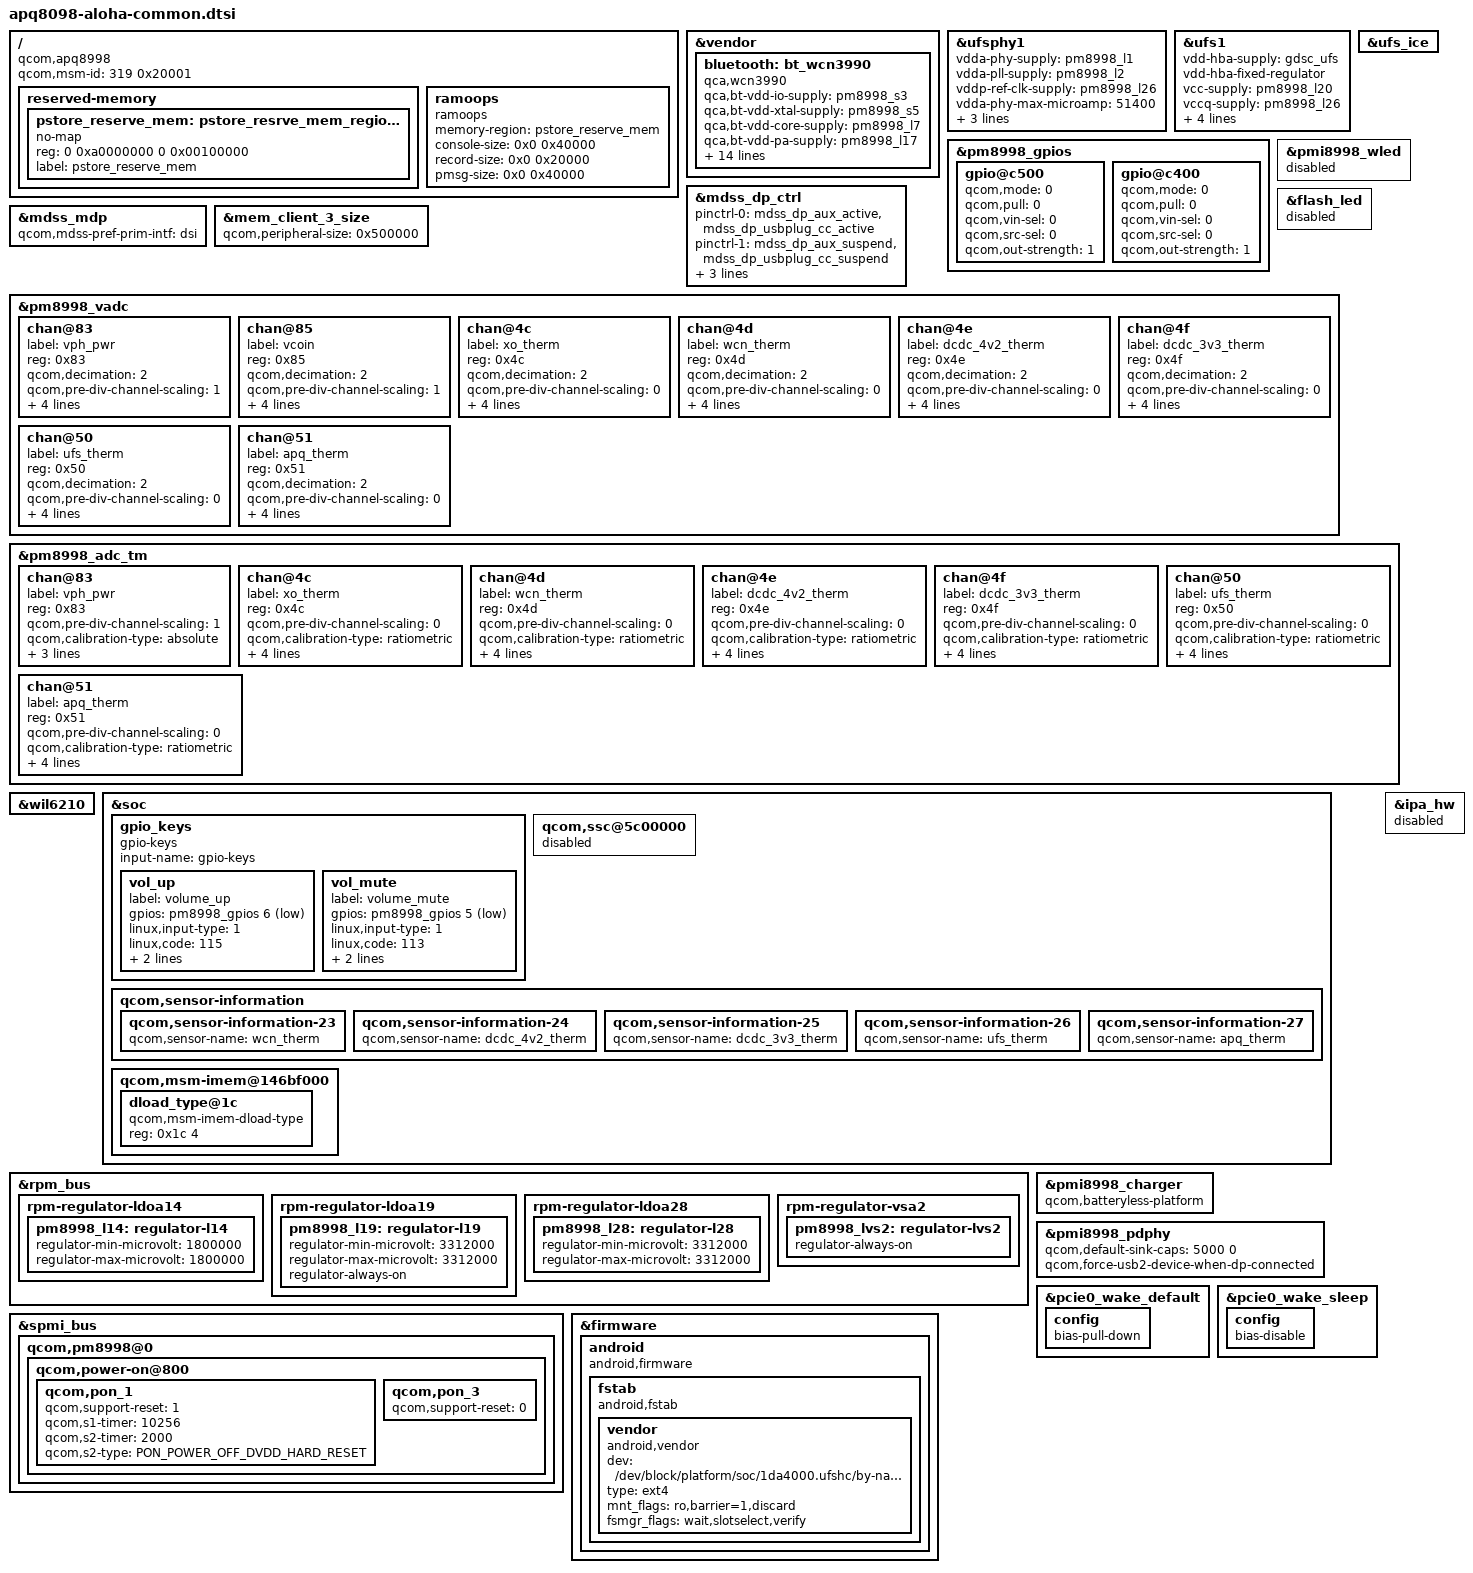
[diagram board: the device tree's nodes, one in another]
/* Copyright (c) 2014-2017, The Linux Foundation. All rights reserved.
 *
 * This program is free software; you can redistribute it and/or modify
 * it under the terms of the GNU General Public License version 2 and
 * only version 2 as published by the Free Software Foundation.
 *
 * This program is distributed in the hope that it will be useful,
 * but WITHOUT ANY WARRANTY; without even the implied warranty of
 * MERCHANTABILITY or FITNESS FOR A PARTICULAR PURPOSE.  See the
 * GNU General Public License for more details.
 */

/dts-v1/;

#include <dt-bindings/interrupt-controller/irq.h>
#include "../qcom/msm8998-v2.1.dtsi"
#include "../qcom/msm8998-pinctrl.dtsi"

/ {
	compatible = "qcom,apq8998", "qcom,apq8098-aloha";
	qcom,msm-id = <319 0x20001>;
};

&vendor {
	bluetooth: bt_wcn3990 {
		compatible = "qca,wcn3990";
		qca,bt-vdd-io-supply = <&pm8998_s3>;
		qca,bt-vdd-xtal-supply = <&pm8998_s5>;
		qca,bt-vdd-core-supply = <&pm8998_l7>;
		qca,bt-vdd-pa-supply = <&pm8998_l17>;
		qca,bt-vdd-ldo-supply = <&pm8998_l25>;
		qca,bt-chip-pwd-supply = <&pmi8998_bob_pin1>;
		clocks = <&clock_gcc clk_rf_clk2_pin>;
		clock-names = "rf_clk2";

		qca,bt-vdd-io-voltage-level = <1352000 1352000>;
		qca,bt-vdd-xtal-voltage-level = <2040000 2040000>;
		qca,bt-vdd-core-voltage-level = <1800000 1800000>;
		qca,bt-vdd-pa-voltage-level = <1304000 1304000>;
		qca,bt-vdd-ldo-voltage-level = <3312000 3312000>;
		qca,bt-chip-pwd-voltage-level = <3600000 3600000>;

		qca,bt-vdd-io-current-level = <1>; /* LPM/PFM */
		qca,bt-vdd-xtal-current-level = <1>; /* LPM/PFM */
		qca,bt-vdd-core-current-level = <1>; /* LPM/PFM */
		qca,bt-vdd-pa-current-level = <1>; /* LPM/PFM */
		qca,bt-vdd-ldo-current-level = <1>; /* LPM/PFM */
	};
};

/ {
	reserved-memory {
		pstore_reserve_mem: pstore_resrve_mem_region@a0000000 {
			no-map;
			reg = <0 0xa0000000 0 0x00100000>;
			label = "pstore_reserve_mem";
		};
	};

	ramoops {
		compatible = "ramoops";
		memory-region = <&pstore_reserve_mem>;
		console-size = <0x0 0x40000>;
		record-size = <0x0 0x20000>;
		pmsg-size = <0x0 0x40000>;
	};
};

&ufsphy1 {
	vdda-phy-supply = <&pm8998_l1>;
	vdda-pll-supply = <&pm8998_l2>;
	vddp-ref-clk-supply = <&pm8998_l26>;
	vdda-phy-max-microamp = <51400>;
	vdda-pll-max-microamp = <14600>;
	vddp-ref-clk-max-microamp = <100>;
	vddp-ref-clk-always-on;
	status = "ok";
};

&ufs1 {
	vdd-hba-supply = <&gdsc_ufs>;
	vdd-hba-fixed-regulator;
	vcc-supply = <&pm8998_l20>;
	vccq-supply = <&pm8998_l26>;
	vccq2-supply = <&pm8998_s4>;
	vcc-max-microamp = <750000>;
	vccq-max-microamp = <560000>;
	vccq2-max-microamp = <750000>;
	status = "ok";
};

&ufs_ice {
	status = "ok";
};

&pm8998_gpios {
	/* GPIO 6 for Vol+ Key */
	gpio@c500 {
		status = "okay";
		qcom,mode = <0>;
		qcom,pull = <0>;
		qcom,vin-sel = <0>;
		qcom,src-sel = <0>;
		qcom,out-strength = <1>;
	};

	/* GPIO 5 for Mute Key */
	gpio@c400 {
		status = "okay";
		qcom,mode = <0>;
		qcom,pull = <0>;
		qcom,vin-sel = <0>;
		qcom,src-sel = <0>;
		qcom,out-strength = <1>;
	};
};

&mdss_dp_ctrl {
	pinctrl-names = "mdss_dp_active", "mdss_dp_sleep";
	pinctrl-0 = <&mdss_dp_aux_active &mdss_dp_usbplug_cc_active>;
	pinctrl-1 = <&mdss_dp_aux_suspend &mdss_dp_usbplug_cc_suspend>;
	qcom,aux-en-gpio = <&tlmm 77 0>;
	qcom,aux-sel-gpio = <&tlmm 78 0>;
	qcom,usbplug-cc-gpio = <&tlmm 38 0>;
};

&mdss_mdp {
	qcom,mdss-pref-prim-intf = "dsi";
};

&pmi8998_wled {
	status = "disabled";
};

&flash_led {
	status = "disabled";
};

&mem_client_3_size {
	qcom,peripheral-size = <0x500000>;
};


&pm8998_vadc {
	chan@83 {
		label = "vph_pwr";
		reg = <0x83>;
		qcom,decimation = <2>;
		qcom,pre-div-channel-scaling = <1>;
		qcom,calibration-type = "absolute";
		qcom,scale-function = <0>;
		qcom,hw-settle-time = <0>;
		qcom,fast-avg-setup = <0>;
	};

	chan@85 {
		label = "vcoin";
		reg = <0x85>;
		qcom,decimation = <2>;
		qcom,pre-div-channel-scaling = <1>;
		qcom,calibration-type = "absolute";
		qcom,scale-function = <0>;
		qcom,hw-settle-time = <0>;
		qcom,fast-avg-setup = <0>;
	};

	chan@4c {
		label = "xo_therm";
		reg = <0x4c>;
		qcom,decimation = <2>;
		qcom,pre-div-channel-scaling = <0>;
		qcom,calibration-type = "ratiometric";
		qcom,scale-function = <4>;
		qcom,hw-settle-time = <2>;
		qcom,fast-avg-setup = <0>;
	};

	chan@4d {
		label = "wcn_therm";
		reg = <0x4d>;
		qcom,decimation = <2>;
		qcom,pre-div-channel-scaling = <0>;
		qcom,calibration-type = "ratiometric";
		qcom,scale-function = <2>;
		qcom,hw-settle-time = <2>;
		qcom,fast-avg-setup = <0>;
	};

	chan@4e {
		label = "dcdc_4v2_therm";
		reg = <0x4e>;
		qcom,decimation = <2>;
		qcom,pre-div-channel-scaling = <0>;
		qcom,calibration-type = "ratiometric";
		qcom,scale-function = <2>;
		qcom,hw-settle-time = <2>;
		qcom,fast-avg-setup = <0>;
	};

	chan@4f {
		label = "dcdc_3v3_therm";
		reg = <0x4f>;
		qcom,decimation = <2>;
		qcom,pre-div-channel-scaling = <0>;
		qcom,calibration-type = "ratiometric";
		qcom,scale-function = <2>;
		qcom,hw-settle-time = <2>;
		qcom,fast-avg-setup = <0>;
	};

	chan@50 {
		label = "ufs_therm";
		reg = <0x50>;
		qcom,decimation = <2>;
		qcom,pre-div-channel-scaling = <0>;
		qcom,calibration-type = "ratiometric";
		qcom,scale-function = <2>;
		qcom,hw-settle-time = <2>;
		qcom,fast-avg-setup = <0>;
	};

	chan@51 {
		label = "apq_therm";
		reg = <0x51>;
		qcom,decimation = <2>;
		qcom,pre-div-channel-scaling = <0>;
		qcom,calibration-type = "ratiometric";
		qcom,scale-function = <2>;
		qcom,hw-settle-time = <2>;
		qcom,fast-avg-setup = <0>;
	};
};

&pm8998_adc_tm {
	chan@83 {
		label = "vph_pwr";
		reg = <0x83>;
		qcom,pre-div-channel-scaling = <1>;
		qcom,calibration-type = "absolute";
		qcom,scale-function = <0>;
		qcom,hw-settle-time = <0>;
		qcom,btm-channel-number = <0x60>;
	};

	chan@4c {
		label = "xo_therm";
		reg = <0x4c>;
		qcom,pre-div-channel-scaling = <0>;
		qcom,calibration-type = "ratiometric";
		qcom,scale-function = <4>;
		qcom,hw-settle-time = <2>;
		qcom,btm-channel-number = <0x68>;
		qcom,thermal-node;
	};

	chan@4d {
		label = "wcn_therm";
		reg = <0x4d>;
		qcom,pre-div-channel-scaling = <0>;
		qcom,calibration-type = "ratiometric";
		qcom,scale-function = <2>;
		qcom,hw-settle-time = <2>;
		qcom,btm-channel-number = <0x70>;
		qcom,thermal-node;
	};

	chan@4e {
		label = "dcdc_4v2_therm";
		reg = <0x4e>;
		qcom,pre-div-channel-scaling = <0>;
		qcom,calibration-type = "ratiometric";
		qcom,scale-function = <4>;
		qcom,hw-settle-time = <2>;
		qcom,btm-channel-number = <0x78>;
		qcom,thermal-node;
	};

	chan@4f {
		label = "dcdc_3v3_therm";
		reg = <0x4f>;
		qcom,pre-div-channel-scaling = <0>;
		qcom,calibration-type = "ratiometric";
		qcom,scale-function = <4>;
		qcom,hw-settle-time = <2>;
		qcom,btm-channel-number = <0x80>;
		qcom,thermal-node;
	};

	chan@50 {
		label = "ufs_therm";
		reg = <0x50>;
		qcom,pre-div-channel-scaling = <0>;
		qcom,calibration-type = "ratiometric";
		qcom,scale-function = <4>;
		qcom,hw-settle-time = <2>;
		qcom,btm-channel-number = <0x88>;
		qcom,thermal-node;
	};

	chan@51 {
		label = "apq_therm";
		reg = <0x51>;
		qcom,pre-div-channel-scaling = <0>;
		qcom,calibration-type = "ratiometric";
		qcom,scale-function = <2>;
		qcom,hw-settle-time = <2>;
		qcom,btm-channel-number = <0x90>;
		qcom,thermal-node;
	};
};

&wil6210 {
	status = "ok";
};

&soc {
	gpio_keys {
		compatible = "gpio-keys";
		input-name = "gpio-keys";
		status = "okay";

		vol_up {
			label = "volume_up";
			gpios = <&pm8998_gpios 6 0x1>;
			linux,input-type = <1>;
			linux,code = <115>;
			gpio-key,wakeup;
			debounce-interval = <15>;
		};

		vol_mute {
			label = "volume_mute";
			gpios = <&pm8998_gpios 5 0x1>;
			linux,input-type = <1>;
			linux,code = <113>;
			gpio-key,wakeup;
			debounce-interval = <15>;
		};
	};

	qcom,ssc@5c00000 {
		status = "disabled";
	};

	qcom,sensor-information {
		qcom,sensor-information-23 {
			qcom,sensor-name = "wcn_therm";
		};

		qcom,sensor-information-24 {
			qcom,sensor-name = "dcdc_4v2_therm";
		};

		qcom,sensor-information-25 {
			qcom,sensor-name = "dcdc_3v3_therm";
		};

		qcom,sensor-information-26 {
			qcom,sensor-name = "ufs_therm";
		};

		qcom,sensor-information-27 {
			qcom,sensor-name = "apq_therm";
		};
	};

	qcom,msm-imem@146bf000 {
		/delete-node/ dload_type@18;

		dload_type@1c {
			compatible = "qcom,msm-imem-dload-type";
			reg = <0x1c 4>;
		};
	};
};

&rpm_bus {
	rpm-regulator-ldoa14 {
		pm8998_l14: regulator-l14 {
			regulator-min-microvolt = <1800000>;
			regulator-max-microvolt = <1800000>;
		};
	};

	rpm-regulator-ldoa19 {
		pm8998_l19: regulator-l19 {
			regulator-min-microvolt = <3312000>;
			regulator-max-microvolt = <3312000>;
			regulator-always-on;
		};
	};

	rpm-regulator-ldoa28 {
		pm8998_l28: regulator-l28 {
			regulator-min-microvolt = <3312000>;
			regulator-max-microvolt = <3312000>;
		};
	};

	rpm-regulator-vsa2 {
		pm8998_lvs2: regulator-lvs2 {
			regulator-always-on;
		};
	};
};

&pmi8998_charger {
       qcom,batteryless-platform;
};

&pmi8998_pdphy {
	qcom,default-sink-caps = <5000 0>; /* 5V @ 0A */
	qcom,force-usb2-device-when-dp-connected;
};

&pcie0_wake_default {
	config {
		bias-pull-down;
	};
};

&pcie0_wake_sleep {
	config {
		bias-disable;
	};
};

&spmi_bus {
	qcom,pm8998@0 {
		qcom,power-on@800 {
			qcom,pon_1 {
				qcom,support-reset = <1>;
				qcom,s1-timer = <10256>;
				qcom,s2-timer = <2000>;
				qcom,s2-type = <PON_POWER_OFF_DVDD_HARD_RESET>;
			};
			qcom,pon_3 {
				qcom,support-reset = <0>;
			};
		};
	};
};

&firmware {
	android {
		compatible = "android,firmware";
		fstab {
			compatible = "android,fstab";
			vendor {
				compatible = "android,vendor";
				dev = "/dev/block/platform/soc/1da4000.ufshc/by-name/vendor";
				type = "ext4";
				mnt_flags = "ro,barrier=1,discard";
				fsmgr_flags = "wait,slotselect,verify";
				status = "ok";
			};
		};
	};
};

&ipa_hw {
	status = "disabled";
};
